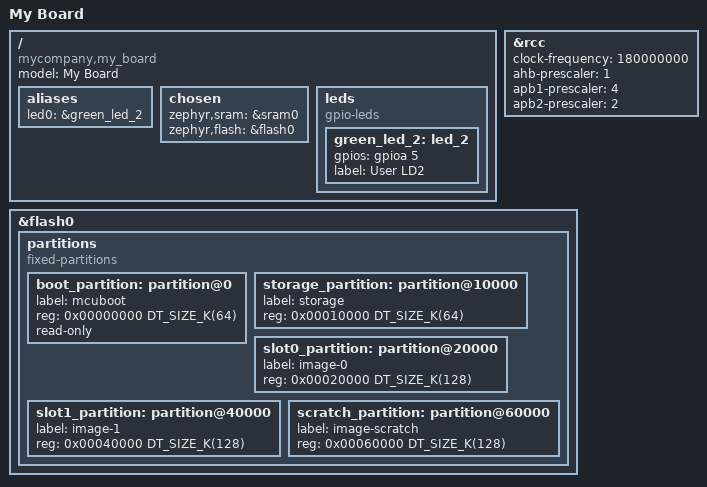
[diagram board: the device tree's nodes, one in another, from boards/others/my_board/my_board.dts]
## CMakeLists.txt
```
cmake_minimum_required(VERSION 3.20.0)
list(APPEND BOARD_ROOT ${CMAKE_CURRENT_SOURCE_DIR})
find_package(Zephyr REQUIRED HINTS $ENV{ZEPHYR_BASE})
project(my_zephyr_app)


target_sources(app PRIVATE src/main.cpp)
```

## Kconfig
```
menuconfig LED_SUBSYSTEM
    bool "LED Subsystem"
    default y

if LED_SUBSYSTEM



choice
    prompt "LED Blink speed"
    default BLINK_SLEEP_1000MS

config BLINK_SLEEP_250MS
  bool "250ms"
config BLINK_SLEEP_500MS
  bool "500ms"
config BLINK_SLEEP_1000MS
  bool "1s"

config BLINK_SLEEP_2000MS
  bool "2s"
endchoice


config BLINK_SLEEP_TIME_MS
    int 
    default 250 if BLINK_SLEEP_250MS
    default 500 if BLINK_SLEEP_500MS
    default 1000 if BLINK_SLEEP_1000MS
    default 2000 if BLINK_SLEEP_2000MS
    default 0
    help
      help string can be multiline
      like this one

  menuconfig Advance_LED_Settings
      bool "Advanced LED settings"
      default n

  if Advance_LED_Settings

      config LED_BRIGHTNESS
        int "LED brightness(0-100)"
        range 0 100
        default 100

      config LED_FADE_DURATION
        int "LED fade duration (0-5000)(ms)"
        range 0 5000
        default 500

        menu "Expert settings"
          visible if Advance_LED_Settings

        config LED_DEBUG
          bool "Enable LED debugging"
        config CUSTOM_BLINK_PATTERN
          bool "Custom blink pattern"
        endmenu
    endif
  endif

config APP_HEARTBEAT_PERIOD_MS
  int "Heartbeat Period(100-2000)ms"
  range 100 2000
  default 500


source "Kconfig.zephyr"
```

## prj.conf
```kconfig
CONFIG_GPIO=y
CONFIG_LOG=y
CONFIG_BLINK_SLEEP_1000MS=y
```

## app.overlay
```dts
/ {
	aliases {
		app-led = &green_led_2;

	};
};
```

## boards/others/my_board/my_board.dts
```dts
/dts-v1/;
#include <zephyr/dt-bindings/clock/stm32f4_clock.h>
#include <st/f4/stm32f446Xe.dtsi>
/ {
	model = "My Board";
	compatible = "mycompany,my_board";

	aliases {
		led0 = &green_led_2;
	};

	chosen {
		zephyr,sram = &sram0;
		zephyr,flash = &flash0;
	};

	leds {
		compatible = "gpio-leds";

		green_led_2: led_2 {
			gpios = <&gpioa 5 GPIO_ACTIVE_HIGH>;
			label = "User LD2";
		};
	};
};
&rcc {
    clock-frequency = <180000000>;
    ahb-prescaler = <1>;
    apb1-prescaler = <4>;
    apb2-prescaler = <2>;
};
&flash0 {
partitions {
	compatible = "fixed-partitions";
	#address-cells = <1>;
	#size-cells = <1>;

	boot_partition: partition@0 {
		label = "mcuboot";
		reg = <0x00000000 DT_SIZE_K(64)>;
		read-only;
	};

	/*
		* The flash starting at 0x00010000 and ending at
		* 0x0001ffff (sectors 16-31) is reserved for use
		* by the application.
		*/
	storage_partition: partition@10000 {
		label = "storage";
		reg = <0x00010000 DT_SIZE_K(64)>;
	};

	slot0_partition: partition@20000 {
		label = "image-0";
		reg = <0x00020000 DT_SIZE_K(128)>;
	};

	slot1_partition: partition@40000 {
		label = "image-1";
		reg = <0x00040000 DT_SIZE_K(128)>;
	};

	scratch_partition: partition@60000 {
		label = "image-scratch";
		reg = <0x00060000 DT_SIZE_K(128)>;
	};
};

};
```

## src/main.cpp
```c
#include <zephyr/drivers/gpio.h>
#include <zephyr/kernel.h>
#include <zephyr/logging/log.h>



/* The devicetree node identifier for the "led0" alias. */
#define LED_NODE DT_ALIAS(app_led)

static const struct gpio_dt_spec led = GPIO_DT_SPEC_GET(LED_NODE, gpios);

LOG_MODULE_REGISTER(main, LOG_LEVEL_INF);

int main(void)
{
    bool led_state = true;

    if (!gpio_is_ready_dt(&led)) return 0;

    if (gpio_pin_configure_dt(&led, GPIO_OUTPUT_ACTIVE) < 0) return 0;

while (1) {
    if (gpio_pin_toggle_dt(&led) < 0) return 0;

    led_state = !led_state;
    LOG_INF("LED state: %s", led_state ? "ON" : "OFF");

    k_msleep(CONFIG_APP_HEARTBEAT_PERIOD_MS);
}

return 0;
    return 0;
}
```
